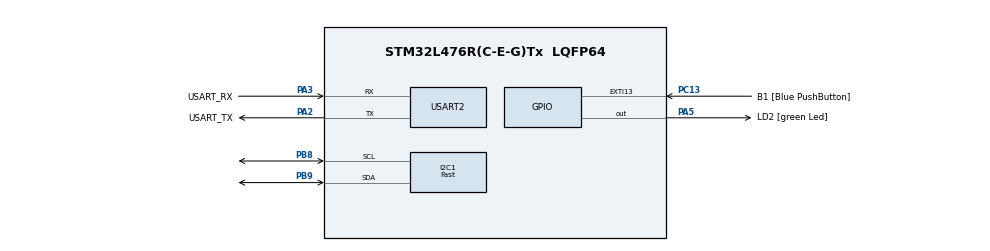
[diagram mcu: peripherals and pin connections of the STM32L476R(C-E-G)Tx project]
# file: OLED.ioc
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Dma.I2C1_TX.0.Direction=DMA_MEMORY_TO_PERIPH
Dma.I2C1_TX.0.Instance=DMA1_Channel6
Dma.I2C1_TX.0.MemDataAlignment=DMA_MDATAALIGN_BYTE
Dma.I2C1_TX.0.MemInc=DMA_MINC_ENABLE
Dma.I2C1_TX.0.Mode=DMA_NORMAL
Dma.I2C1_TX.0.PeriphDataAlignment=DMA_PDATAALIGN_BYTE
Dma.I2C1_TX.0.PeriphInc=DMA_PINC_DISABLE
Dma.I2C1_TX.0.Priority=DMA_PRIORITY_LOW
Dma.Request0=I2C1_TX
I2C1.CustomTiming=Enabled
I2C1.I2C_Speed_Mode=I2C_Fast
I2C1.Speed=200
I2C1.Timing=0x10909CEC
Mcu.Family=STM32L4
Mcu.Name=STM32L476R(C-E-G)Tx
Mcu.Package=LQFP64
NVIC.DMA1_Channel6_IRQn=true\:0\:0\:false\:false\:true\:false\:true\:true
NVIC.EXTI15_10_IRQn=true\:0\:0\:false\:false\:true\:true\:true\:true
NVIC.I2C1_EV_IRQn=true\:0\:0\:false\:false\:true\:true\:true\:true
NVIC.PriorityGroup=NVIC_PRIORITYGROUP_4
PA13\ (JTMS-SWDIO).GPIO_Label=TMS
PA13\ (JTMS-SWDIO).Mode=Serial_Wire
PA13\ (JTMS-SWDIO).Signal=SYS_JTMS-SWDIO
PA14\ (JTCK-SWCLK).GPIO_Label=TCK
PA14\ (JTCK-SWCLK).Mode=Serial_Wire
PA14\ (JTCK-SWCLK).Signal=SYS_JTCK-SWCLK
PA2.GPIO_Label=USART_TX
PA2.GPIO_Mode=GPIO_MODE_AF_PP
PA2.GPIO_PuPd=GPIO_NOPULL
PA2.GPIO_Speed=GPIO_SPEED_FREQ_VERY_HIGH
PA2.Mode=Asynchronous
PA2.Signal=USART2_TX
PA3.GPIO_Label=USART_RX
PA3.GPIO_Mode=GPIO_MODE_AF_PP
PA3.GPIO_PuPd=GPIO_NOPULL
PA3.GPIO_Speed=GPIO_SPEED_FREQ_VERY_HIGH
PA3.Mode=Asynchronous
PA3.Signal=USART2_RX
PA5.GPIO_Label=LD2 [green Led]
PA5.GPIO_ModeDefaultOutputPP=GPIO_MODE_OUTPUT_PP
PA5.GPIO_PuPd=GPIO_NOPULL
PA5.GPIO_Speed=GPIO_SPEED_FREQ_LOW
PA5.Signal=GPIO_Output
PB3\ (JTDO-TRACESWO).GPIO_Label=SWO
PB3\ (JTDO-TRACESWO).Signal=SYS_JTDO-SWO
PB8.GPIO_Pu=GPIO_PULLUP
PB8.Mode=I2C
PB8.Signal=I2C1_SCL
PB9.GPIO_Pu=GPIO_PULLUP
PB9.Mode=I2C
PB9.Signal=I2C1_SDA
PC13.GPIO_Label=B1 [Blue PushButton]
PC13.GPIO_ModeDefaultEXTI=GPIO_MODE_IT_FALLING
PC13.GPIO_PuPd=GPIO_NOPULL
PC13.Signal=GPXTI13
PC14-OSC32_IN\ (PC14).Mode=LSE-External-Oscillator
PC14-OSC32_IN\ (PC14).Signal=RCC_OSC32_IN
PC15-OSC32_OUT\ (PC15).Mode=LSE-External-Oscillator
PC15-OSC32_OUT\ (PC15).Signal=RCC_OSC32_OUT
PH0-OSC_IN\ (PH0).Signal=RCC_OSC_IN
PH1-OSC_OUT\ (PH1).Signal=RCC_OSC_OUT
ProjectManager.HeapSize=0x100
ProjectManager.StackSize=0x400
ProjectManager.TargetToolchain=STM32CubeIDE
RCC.ADCFreq_Value=64000000
RCC.AHBFreq_Value=80000000
RCC.APB1Freq_Value=80000000
RCC.APB1TimFreq_Value=80000000
RCC.APB2Freq_Value=80000000
RCC.APB2TimFreq_Value=80000000
RCC.CortexFreq_Value=80000000
RCC.HCLKFreq_Value=80000000
RCC.HSE_VALUE=8000000
RCC.HSI_VALUE=16000000
RCC.MSI_VALUE=4000000
RCC.PLLN=10
RCC.PLLSourceVirtual=RCC_PLLSOURCE_HSI
RCC.PREFETCH_ENABLE=1
RCC.SYSCLKFreq_VALUE=80000000
RCC.SYSCLKSource=RCC_SYSCLKSOURCE_PLLCLK
RCC.USBFreq_Value=64000000
RCC.VCOOutputFreq_Value=160000000
USART2.VirtualMode-Asynchronous=VM_ASYNC
board=NUCLEO-L476RG

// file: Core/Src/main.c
/* USER CODE BEGIN Header */
/**
  ******************************************************************************
  * @file           : main.c
  * @brief          : Main program body
  ******************************************************************************
  * @attention
  *
  * Copyright (c) 2023 STMicroelectronics.
  * All rights reserved.
  *
  * This software is licensed under terms that can be found in the LICENSE file
  * in the root directory of this software component.
  * If no LICENSE file comes with this software, it is provided AS-IS.
  *
  ******************************************************************************
  */
/* USER CODE END Header */
#include "main.h"

/* USER CODE BEGIN Includes */
#include "SSD1309.h"
#include "shift_display.h"
#define TX_I2C_DATALENGHT 256
/* USER CODE END Includes */

/* USER CODE BEGIN PTD */
	extern uint8_t SSD1309_tz_buff[1025];
/* USER CODE END PTD */

void SystemClock_Config(void);
static void MX_GPIO_Init(void);
static void MX_I2C1_Init(void);
static void MX_DMA_Init(void);
static void MX_USART2_UART_Init(void);

int main(void)
{
  /* USER CODE BEGIN 1 */
	uint8_t val=0;
  /* USER CODE END 1 */

  /* MCU Configuration--------------------------------------------------------*/

  /* Reset of all peripherals, Initializes the Flash interface and the Systick. */
  HAL_Init();

  /* Configure the system clock */
  SystemClock_Config();

  /* Initialize all configured peripherals */
  MX_GPIO_Init();
  MX_I2C1_Init();
  MX_DMA_Init();
  MX_USART2_UART_Init();
  /* USER CODE BEGIN 2 */
  SSD1309_init();
  shift_display_fill_buffer("1234567890 qwertasdf");
  shift_display_handler();
  /* USER CODE END 2 */

  /* Infinite loop */
  while (1)
  {
	  for(uint32_t i=0; i< 170000; i++)
	  	  {
	  		  asm("nop");

	  	  }

	  	 shift_display_handler();
  }
}

void SystemClock_Config(void)
{
  LL_FLASH_SetLatency(LL_FLASH_LATENCY_4);
  while(LL_FLASH_GetLatency()!= LL_FLASH_LATENCY_4)
  {
  }
  LL_PWR_SetRegulVoltageScaling(LL_PWR_REGU_VOLTAGE_SCALE1);
  LL_RCC_HSI_Enable();

   /* Wait till HSI is ready */
  while(LL_RCC_HSI_IsReady() != 1)
  {

  }
  LL_RCC_HSI_SetCalibTrimming(16);
  LL_RCC_PLL_ConfigDomain_SYS(LL_RCC_PLLSOURCE_HSI, LL_RCC_PLLM_DIV_1, 10, LL_RCC_PLLR_DIV_2);
  LL_RCC_PLL_EnableDomain_SYS();
  LL_RCC_PLL_Enable();

   /* Wait till PLL is ready */
  while(LL_RCC_PLL_IsReady() != 1)
  {

  }
  LL_RCC_SetSysClkSource(LL_RCC_SYS_CLKSOURCE_PLL);

   /* Wait till System clock is ready */
  while(LL_RCC_GetSysClkSource() != LL_RCC_SYS_CLKSOURCE_STATUS_PLL)
  {

  }
  LL_RCC_SetAHBPrescaler(LL_RCC_SYSCLK_DIV_1);
  LL_RCC_SetAPB1Prescaler(LL_RCC_APB1_DIV_1);
  LL_RCC_SetAPB2Prescaler(LL_RCC_APB2_DIV_1);
  LL_SetSystemCoreClock(80000000);

   /* Update the time base */
  if (HAL_InitTick (TICK_INT_PRIORITY) != HAL_OK)
  {
    Error_Handler();
  }
}

static void MX_I2C1_Init(void)
{

  LL_I2C_InitTypeDef I2C_InitStruct = {0};

  LL_GPIO_InitTypeDef GPIO_InitStruct = {0};

  LL_RCC_SetI2CClockSource(LL_RCC_I2C1_CLKSOURCE_PCLK1);

  LL_AHB2_GRP1_EnableClock(LL_AHB2_GRP1_PERIPH_GPIOB);
  /**I2C1 GPIO Configuration
  PB8   ------> I2C1_SCL
  PB9   ------> I2C1_SDA
  */
  GPIO_InitStruct.Pin = LL_GPIO_PIN_8|LL_GPIO_PIN_9;
  GPIO_InitStruct.Mode = LL_GPIO_MODE_ALTERNATE;
  GPIO_InitStruct.Speed = LL_GPIO_SPEED_FREQ_VERY_HIGH;
  GPIO_InitStruct.OutputType = LL_GPIO_OUTPUT_OPENDRAIN;
  GPIO_InitStruct.Pull = LL_GPIO_PULL_UP;
  GPIO_InitStruct.Alternate = LL_GPIO_AF_4;
  LL_GPIO_Init(GPIOB, &GPIO_InitStruct);

  /* Peripheral clock enable */
  LL_APB1_GRP1_EnableClock(LL_APB1_GRP1_PERIPH_I2C1);

  /* I2C1 DMA Init */

  /* I2C1_TX Init */
  LL_DMA_SetPeriphRequest(DMA1, LL_DMA_CHANNEL_6, LL_DMA_REQUEST_3);

  LL_DMA_SetDataTransferDirection(DMA1, LL_DMA_CHANNEL_6, LL_DMA_DIRECTION_MEMORY_TO_PERIPH);

  LL_DMA_SetChannelPriorityLevel(DMA1, LL_DMA_CHANNEL_6, LL_DMA_PRIORITY_LOW);

  LL_DMA_SetMode(DMA1, LL_DMA_CHANNEL_6, LL_DMA_MODE_NORMAL);

  LL_DMA_SetPeriphIncMode(DMA1, LL_DMA_CHANNEL_6, LL_DMA_PERIPH_NOINCREMENT);

  LL_DMA_SetMemoryIncMode(DMA1, LL_DMA_CHANNEL_6, LL_DMA_MEMORY_INCREMENT);

  LL_DMA_SetPeriphSize(DMA1, LL_DMA_CHANNEL_6, LL_DMA_PDATAALIGN_BYTE);

  LL_DMA_SetMemorySize(DMA1, LL_DMA_CHANNEL_6, LL_DMA_MDATAALIGN_BYTE);

  /* I2C1 interrupt Init */
  NVIC_SetPriority(I2C1_EV_IRQn, NVIC_EncodePriority(NVIC_GetPriorityGrouping(),0, 0));
  NVIC_EnableIRQ(I2C1_EV_IRQn);

  /* USER CODE BEGIN I2C1_Init 1 */

    // Send a start signal.
   // I2C2->CR2     |=  ( I2C_CR2_START );

 // DMA1_Channel6->CCR = TX_I2C_DATALENGHT;
  /* USER CODE END I2C1_Init 1 */

  /** I2C Initialization
  */
  LL_I2C_EnableAutoEndMode(I2C1);
  LL_I2C_DisableOwnAddress2(I2C1);
  LL_I2C_DisableGeneralCall(I2C1);
  LL_I2C_EnableClockStretching(I2C1);
  I2C_InitStruct.PeripheralMode = LL_I2C_MODE_I2C;
  I2C_InitStruct.Timing = 0x00909CEC;
  I2C_InitStruct.AnalogFilter = LL_I2C_ANALOGFILTER_ENABLE;
  I2C_InitStruct.DigitalFilter = 0;
  I2C_InitStruct.OwnAddress1 = 0;
  I2C_InitStruct.TypeAcknowledge = LL_I2C_ACK;
  I2C_InitStruct.OwnAddrSize = LL_I2C_OWNADDRESS1_7BIT;
  LL_I2C_Init(I2C1, &I2C_InitStruct);
  LL_I2C_SetOwnAddress2(I2C1, 0, LL_I2C_OWNADDRESS2_NOMASK);
  /* USER CODE BEGIN I2C1_Init 2 */

     // Enable I2C DMA requests.

  /* USER CODE END I2C1_Init 2 */

}

static void MX_USART2_UART_Init(void)
{

  LL_USART_InitTypeDef USART_InitStruct = {0};

  LL_GPIO_InitTypeDef GPIO_InitStruct = {0};

  LL_RCC_SetUSARTClockSource(LL_RCC_USART2_CLKSOURCE_PCLK1);

  /* Peripheral clock enable */
  LL_APB1_GRP1_EnableClock(LL_APB1_GRP1_PERIPH_USART2);

  LL_AHB2_GRP1_EnableClock(LL_AHB2_GRP1_PERIPH_GPIOA);
  /**USART2 GPIO Configuration
  PA2   ------> USART2_TX
  PA3   ------> USART2_RX
  */
  GPIO_InitStruct.Pin = USART_TX_Pin|USART_RX_Pin;
  GPIO_InitStruct.Mode = LL_GPIO_MODE_ALTERNATE;
  GPIO_InitStruct.Speed = LL_GPIO_SPEED_FREQ_VERY_HIGH;
  GPIO_InitStruct.OutputType = LL_GPIO_OUTPUT_PUSHPULL;
  GPIO_InitStruct.Pull = LL_GPIO_PULL_NO;
  GPIO_InitStruct.Alternate = LL_GPIO_AF_7;
  LL_GPIO_Init(GPIOA, &GPIO_InitStruct);

  USART_InitStruct.BaudRate = 115200;
  USART_InitStruct.DataWidth = LL_USART_DATAWIDTH_8B;
  USART_InitStruct.StopBits = LL_USART_STOPBITS_1;
  USART_InitStruct.Parity = LL_USART_PARITY_NONE;
  USART_InitStruct.TransferDirection = LL_USART_DIRECTION_TX_RX;
  USART_InitStruct.HardwareFlowControl = LL_USART_HWCONTROL_NONE;
  USART_InitStruct.OverSampling = LL_USART_OVERSAMPLING_16;
  LL_USART_Init(USART2, &USART_InitStruct);
  LL_USART_ConfigAsyncMode(USART2);
  LL_USART_Enable(USART2);

}

static void MX_DMA_Init(void)
{

  /* DMA controller clock enable */
  __HAL_RCC_DMA1_CLK_ENABLE();

  DMA1_CSELR->CSELR |= (3 << 20);
  DMA1_Channel6->CPAR = (uint32_t) & (I2C1->TXDR);
  //DMA1_Channel6->CMAR = (uint32_t) & (TX_DMA_buffer);
  DMA1_Channel6->CNDTR = TX_I2C_DATALENGHT;
  DMA1_Channel6->CCR |= DMA_CCR_DIR | DMA_CCR_PL_1 | DMA_CCR_TCIE | DMA_CCR_MINC | DMA_CCR_HTIE ;

  /* DMA interrupt init */
  /* DMA1_Channel6_IRQn interrupt configuration */
  NVIC_SetPriority(DMA1_Channel6_IRQn, NVIC_EncodePriority(NVIC_GetPriorityGrouping(),0, 0));
  NVIC_EnableIRQ(DMA1_Channel6_IRQn);

}

static void MX_GPIO_Init(void)
{
  LL_EXTI_InitTypeDef EXTI_InitStruct = {0};
  LL_GPIO_InitTypeDef GPIO_InitStruct = {0};

  /* GPIO Ports Clock Enable */
  LL_AHB2_GRP1_EnableClock(LL_AHB2_GRP1_PERIPH_GPIOC);
  LL_AHB2_GRP1_EnableClock(LL_AHB2_GRP1_PERIPH_GPIOH);
  LL_AHB2_GRP1_EnableClock(LL_AHB2_GRP1_PERIPH_GPIOA);
  LL_AHB2_GRP1_EnableClock(LL_AHB2_GRP1_PERIPH_GPIOB);

  /**/
  LL_GPIO_ResetOutputPin(LD2_GPIO_Port, LD2_Pin);

  /**/
  LL_SYSCFG_SetEXTISource(LL_SYSCFG_EXTI_PORTC, LL_SYSCFG_EXTI_LINE13);

  /**/
  EXTI_InitStruct.Line_0_31 = LL_EXTI_LINE_13;
  EXTI_InitStruct.Line_32_63 = LL_EXTI_LINE_NONE;
  EXTI_InitStruct.LineCommand = ENABLE;
  EXTI_InitStruct.Mode = LL_EXTI_MODE_IT;
  EXTI_InitStruct.Trigger = LL_EXTI_TRIGGER_FALLING;
  LL_EXTI_Init(&EXTI_InitStruct);

  /**/
  LL_GPIO_SetPinPull(B1_GPIO_Port, B1_Pin, LL_GPIO_PULL_NO);

  /**/
  LL_GPIO_SetPinMode(B1_GPIO_Port, B1_Pin, LL_GPIO_MODE_INPUT);

  /**/
  GPIO_InitStruct.Pin = LD2_Pin;
  GPIO_InitStruct.Mode = LL_GPIO_MODE_OUTPUT;
  GPIO_InitStruct.Speed = LL_GPIO_SPEED_FREQ_LOW;
  GPIO_InitStruct.OutputType = LL_GPIO_OUTPUT_PUSHPULL;
  GPIO_InitStruct.Pull = LL_GPIO_PULL_NO;
  LL_GPIO_Init(LD2_GPIO_Port, &GPIO_InitStruct);

  /* EXTI interrupt init*/
  NVIC_SetPriority(EXTI15_10_IRQn, NVIC_EncodePriority(NVIC_GetPriorityGrouping(),0, 0));
  NVIC_EnableIRQ(EXTI15_10_IRQn);

}

void Error_Handler(void)
{
  __disable_irq();
  while (1)
  {
  }
}
